# ATSAME54P19A device description
Architecture: CORTEX-M4; Family: SAME; Series: SAME54
Registers are 32-bit, read-write, reset 0x0 unless marked. A register's access mark holds for its fields unless they carry their own. Offsets are from the block's base; [hi:lo] are bit positions; lines under a group give offsets from that group; {n}, {i} and the like mark numbered series.

## HMATRIXB — HSB Matrix
Instances: HMATRIX 0x4100C000
{0x80+8i} PRS[{i}] (i=0..15) group
  0x00 PRAS — Priority A for Slave
  0x04 PRBS — Priority B for Slave

## ICM — Integrity Check Monitor
Instances: ICM 0x42002C00
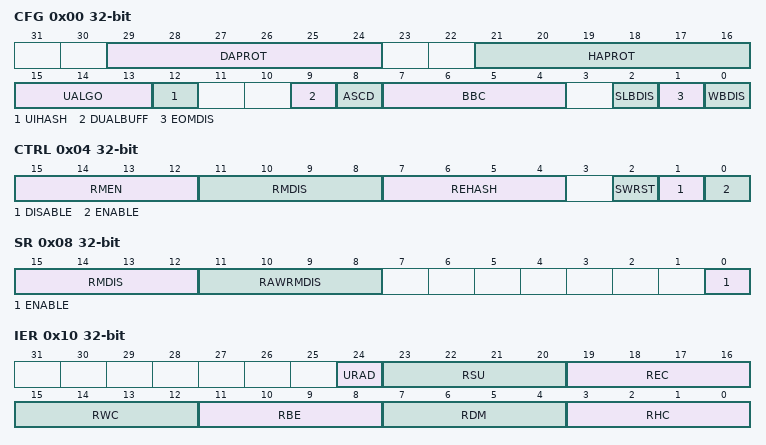
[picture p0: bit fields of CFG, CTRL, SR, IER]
0x00 CFG — Configuration
  [29:24] DAPROT — Region Descriptor Area Protection
  [21:16] HAPROT — Region Hash Area Protection
  [15:13] UALGO — User SHA Algorithm
    0=SHA1 (SHA1 Algorithm); 1=SHA256 (SHA256 Algorithm); 4=SHA224 (SHA224 Algorithm)
  [12] UIHASH — User Initial Hash Value
  [9] DUALBUFF — Dual Input Buffer
  [8] ASCD — Automatic Switch To Compare Digest
  [7:4] BBC — Bus Burden Control
  [2] SLBDIS — Secondary List Branching Disable
  [1] EOMDIS — End of Monitoring Disable
  [0] WBDIS — Write Back Disable
0x04 CTRL wo reset not defined — Control
  [15:12] RMEN — Region Monitoring Enable
  [11:8] RMDIS — Region Monitoring Disable
  [7:4] REHASH — Recompute Internal Hash
  [2] SWRST — Software Reset
  [1] DISABLE — ICM Disable Register
  [0] ENABLE — ICM Enable
0x08 SR ro — Status
  [15:12] RMDIS — Region Monitoring Disabled Status
  [11:8] RAWRMDIS — RAW Region Monitoring Disabled Status
  [0] ENABLE — ICM Controller Enable Register
0x10 IER wo reset not defined (atomic set of IMR) — Interrupt Enable
  [24] URAD — Undefined Register Access Detection Interrupt Enable
  [23:20] RSU — Region Status Updated Interrupt Disable
  [19:16] REC — Region End bit Condition Detected Interrupt Enable
  [15:12] RWC — Region Wrap Condition detected Interrupt Enable
  [11:8] RBE — Region Bus Error Interrupt Enable
  [7:4] RDM — Region Digest Mismatch Interrupt Enable
  [3:0] RHC — Region Hash Completed Interrupt Enable
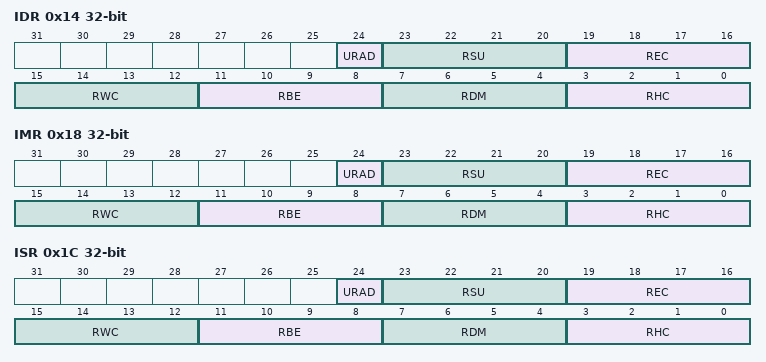
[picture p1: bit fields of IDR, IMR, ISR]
0x14 IDR wo (atomic clear of IMR) — Interrupt Disable
  [24] URAD — Undefined Register Access Detection Interrupt Disable
  [23:20] RSU — Region Status Updated Interrupt Disable
  [19:16] REC — Region End bit Condition detected Interrupt Disable
  [15:12] RWC — Region Wrap Condition Detected Interrupt Disable
  [11:8] RBE — Region Bus Error Interrupt Disable
  [7:4] RDM — Region Digest Mismatch Interrupt Disable
  [3:0] RHC — Region Hash Completed Interrupt Disable
0x18 IMR ro — Interrupt Mask
  [24] URAD — Undefined Register Access Detection Interrupt Mask
  [23:20] RSU — Region Status Updated Interrupt Mask
  [19:16] REC — Region End bit Condition Detected Interrupt Mask
  [15:12] RWC — Region Wrap Condition Detected Interrupt Mask
  [11:8] RBE — Region Bus Error Interrupt Mask
  [7:4] RDM — Region Digest Mismatch Interrupt Mask
  [3:0] RHC — Region Hash Completed Interrupt Mask
0x1C ISR ro — Interrupt Status
  [24] URAD — Undefined Register Access Detection Status
  [23:20] RSU — Region Status Updated Detected
  [19:16] REC — Region End bit Condition Detected
  [15:12] RWC — Region Wrap Condition Detected
  [11:8] RBE — Region Bus Error
  [7:4] RDM — Region Digest Mismatch
  [3:0] RHC — Region Hash Completed
0x20 UASR ro — Undefined Access Status
  [2:0] URAT — Undefined Register Access Trace
    0=UNSPEC_STRUCT_MEMBER (Unspecified structure member set to one detected when the descriptor is loaded); 1=CFG_MODIFIED (CFG modified during active monitoring); 2=DSCR_MODIFIED (DSCR modified during active monitoring); 3=HASH_MODIFIED (HASH modified during active monitoring); 4=READ_ACCESS (Write-only register read access)
0x30 DSCR — Region Descriptor Area Start Address
  [31:6] DASA — Descriptor Area Start Address
0x34 HASH — Region Hash Area Start Address
  [31:7] HASA — Hash Area Start Address
{0x38+4i} UIHVAL[{i}] (i=0..7) wo — User Initial Hash Value n
  [31:0] VAL — Initial Hash Value

## ICM_DESCRIPTOR — Integrity Check Monitor
0x00 RADDR reset not defined — Region Start Address
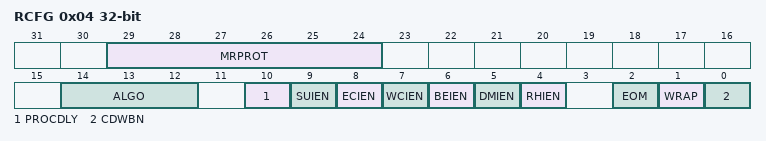
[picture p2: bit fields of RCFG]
0x04 RCFG — Region Configuration
  [29:24] MRPROT — Memory Region AHB Protection
  [14:12] ALGO — SHA Algorithm
  [10] PROCDLY — SHA Processing Delay
    0=SHORT; 1=LONG
  [9] SUIEN — Region Status Updated Interrupt Enable
    0=EN; 1=DIS
  [8] ECIEN — Region End bit Condition detected Interrupt Enable
    0=EN; 1=DIS
  [7] WCIEN — Region Wrap Condition Detected Interrupt Enable
    0=EN; 1=DIS
  [6] BEIEN — Region Bus Error Interrupt Enable
    0=EN; 1=DIS
  [5] DMIEN — Region Digest Mismatch Interrupt Enable
    0=EN; 1=DIS
  [4] RHIEN — Region Hash Interrupt Enable
    0=EN; 1=DIS
  [2] EOM — End of Monitoring
    0=NO; 1=YES
  [1] WRAP — Region Wrap
    0=NO; 1=YES
  [0] CDWBN — Compare Digest Write Back
    0=WRBA; 1=COMP
0x08 RCTRL reset not defined — Region Control
  [15:0] TRSIZE — Transfer Size
0x0C RNEXT reset not defined — Region Next Address

## Notices in the file
Copyright (c) 2018 Microchip Technology Inc.
SPDX-License-Identifier: Apache-2.0
Licensed under the Apache License, Version 2.0 (the "License");
you may not use this file except in compliance with the License.
You may obtain a copy of the License at
http://www.apache.org/licenses/LICENSE-2.0
Unless required by applicable law or agreed to in writing, software
distributed under the License is distributed on an "AS IS" BASIS,
WITHOUT WARRANTIES OR CONDITIONS OF ANY KIND, either express or implied.
See the License for the specific language governing permissions and
limitations under the License.
